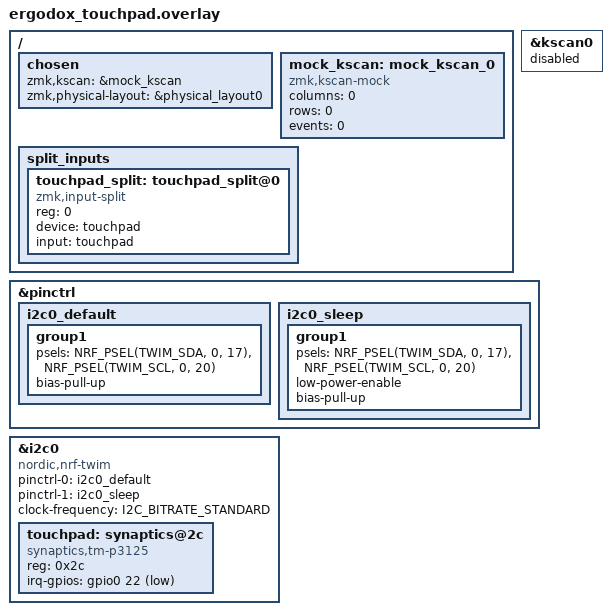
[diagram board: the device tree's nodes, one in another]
/*
 * Copyright (c) 2026 ErgoDox Wireless Project
 * SPDX-License-Identifier: MIT
 */

#include "ergodox.dtsi"
#include <dt-bindings/pinctrl/nrf-pinctrl.h>

/ {
    chosen {
        zmk,kscan = &mock_kscan;
        zmk,physical-layout = &physical_layout0;
    };

    mock_kscan: mock_kscan_0 {
        compatible = "zmk,kscan-mock";
        columns = <0>;
        rows = <0>;
        events = <0>;
    };

    split_inputs {
        #address-cells = <1>;
        #size-cells = <0>;

        touchpad_split: touchpad_split@0 {
            compatible = "zmk,input-split";
            reg = <0>;
            device = <&touchpad>;
            input = <&touchpad>;
        };
    };
};

&kscan0 {
    status = "disabled";
};

&pinctrl {
    i2c0_default: i2c0_default {
        group1 {
            psels = <NRF_PSEL(TWIM_SDA, 0, 17)>,
                    <NRF_PSEL(TWIM_SCL, 0, 20)>;
            bias-pull-up;
        };
    };

    i2c0_sleep: i2c0_sleep {
        group1 {
            psels = <NRF_PSEL(TWIM_SDA, 0, 17)>,
                    <NRF_PSEL(TWIM_SCL, 0, 20)>;
            low-power-enable;
            bias-pull-up;
        };
    };
};

&i2c0 {
    status = "okay";
    compatible = "nordic,nrf-twim";
    pinctrl-0 = <&i2c0_default>;
    pinctrl-1 = <&i2c0_sleep>;
    pinctrl-names = "default", "sleep";
    clock-frequency = <I2C_BITRATE_STANDARD>;

    touchpad: synaptics@2c {
        compatible = "synaptics,tm-p3125";
        reg = <0x2c>;
        status = "okay";
        irq-gpios = <&gpio0 22 (GPIO_ACTIVE_LOW | GPIO_PULL_UP)>;
    };
};

